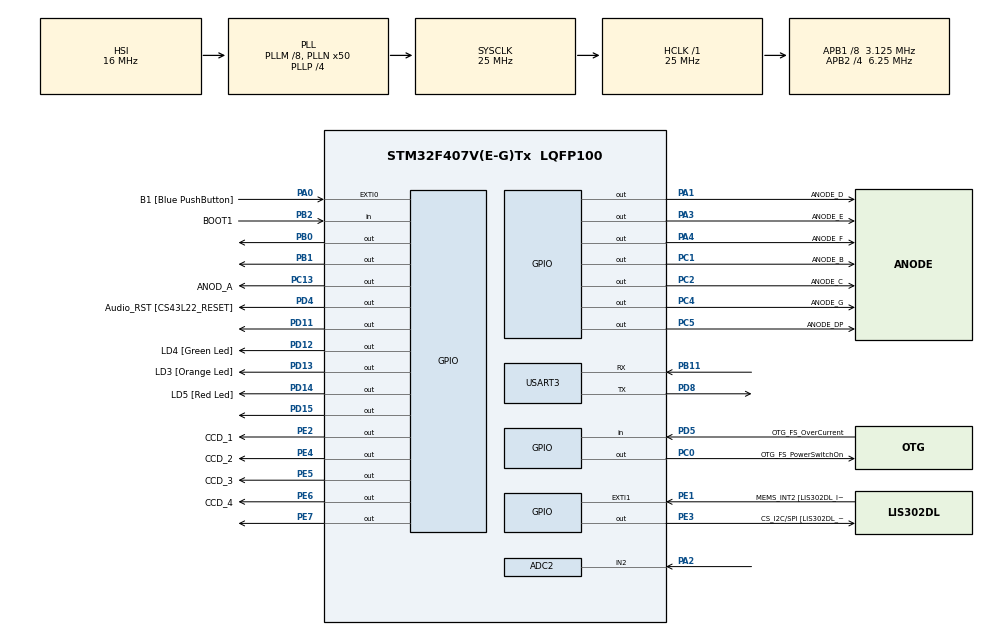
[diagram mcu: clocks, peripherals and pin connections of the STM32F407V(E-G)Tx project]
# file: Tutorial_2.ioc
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ADC2.Channel-0\#ChannelRegularConversion=ADC_CHANNEL_2
ADC2.ClockPrescaler=ADC_CLOCK_SYNC_PCLK_DIV2
ADC2.ContinuousConvMode=DISABLE
ADC2.DMAContinuousRequests=DISABLE
ADC2.DataAlign=ADC_DATAALIGN_RIGHT
ADC2.DiscontinuousConvMode=DISABLE
ADC2.EOCSelection=ADC_EOC_SINGLE_CONV
ADC2.EnableAnalogWatchDog=false
ADC2.ExternalTrigConv=ADC_EXTERNALTRIGCONV_T3_TRGO
ADC2.ExternalTrigConvEdge=ADC_EXTERNALTRIGCONVEDGE_RISING
ADC2.InjNumberOfConversion=0
ADC2.NbrOfConversion=1
ADC2.NbrOfConversionFlag=1
ADC2.Rank-0\#ChannelRegularConversion=1
ADC2.Resolution=ADC_RESOLUTION_8B
ADC2.SamplingTime-0\#ChannelRegularConversion=ADC_SAMPLETIME_3CYCLES
ADC2.ScanConvMode=DISABLE
Mcu.Family=STM32F4
Mcu.Name=STM32F407V(E-G)Tx
Mcu.Package=LQFP100
NVIC.PriorityGroup=NVIC_PRIORITYGROUP_0
NVIC.TIM2_IRQn=true\:0\:0\:false\:false\:true\:true
NVIC.USART3_IRQn=true\:0\:0\:false\:false\:true\:true
PA0-WKUP.GPIO_Label=B1 [Blue PushButton]
PA0-WKUP.GPIO_ModeDefaultEXTI=GPIO_MODE_EVT_RISING
PA0-WKUP.GPIO_PuPd=GPIO_NOPULL
PA0-WKUP.Signal=GPXTI0
PA1.GPIO_Label=ANODE_D
PA1.Signal=GPIO_Output
PA10.GPIO_Label=OTG_FS_ID
PA10.GPIO_Mode=GPIO_MODE_AF_PP
PA10.GPIO_PuPd=GPIO_NOPULL
PA10.GPIO_Speed=GPIO_SPEED_FREQ_LOW
PA10.Signal=USB_OTG_FS_ID
PA11.GPIO_Label=OTG_FS_DM
PA11.GPIO_Mode=GPIO_MODE_AF_PP
PA11.GPIO_PuPd=GPIO_NOPULL
PA11.GPIO_Speed=GPIO_SPEED_FREQ_LOW
PA11.Signal=USB_OTG_FS_DM
PA12.GPIO_Label=OTG_FS_DP
PA12.GPIO_Mode=GPIO_MODE_AF_PP
PA12.GPIO_PuPd=GPIO_NOPULL
PA12.GPIO_Speed=GPIO_SPEED_FREQ_LOW
PA12.Signal=USB_OTG_FS_DP
PA13.GPIO_Label=SWDIO
PA13.Signal=SYS_JTMS-SWDIO
PA14.GPIO_Label=SWCLK
PA14.Signal=SYS_JTCK-SWCLK
PA2.Signal=ADCx_IN2
PA3.GPIO_Label=ANODE_E
PA3.Signal=GPIO_Output
PA4.GPIO_Label=ANODE_F
PA4.Signal=GPIO_Output
PA5.GPIO_Label=SPI1_SCK [LIS302DL_SCL/SPC]
PA5.GPIO_Mode=GPIO_MODE_AF_PP
PA5.GPIO_PuPd=GPIO_NOPULL
PA5.GPIO_Speed=GPIO_SPEED_FREQ_LOW
PA5.Signal=SPI1_SCK
PA6.GPIO_Label=SPI1_MISO [LIS302DL_SDO]
PA6.GPIO_Mode=GPIO_MODE_AF_PP
PA6.GPIO_PuPd=GPIO_NOPULL
PA6.GPIO_Speed=GPIO_SPEED_FREQ_LOW
PA6.Signal=SPI1_MISO
PA7.GPIO_Label=SPI1_MOSI [LIS302DL_SDA/SDI/SDO]
PA7.GPIO_Mode=GPIO_MODE_AF_PP
PA7.GPIO_PuPd=GPIO_NOPULL
PA7.GPIO_Speed=GPIO_SPEED_FREQ_LOW
PA7.Signal=SPI1_MOSI
PA9.GPIO_Label=VBUS_FS
PA9.GPIO_Mode=GPIO_MODE_INPUT
PA9.GPIO_PuPd=GPIO_NOPULL
PA9.Signal=USB_OTG_FS_VBUS
PB0.Signal=GPIO_Output
PB1.Signal=GPIO_Output
PB10.GPIO_Label=CLK_IN [MP45DT02_CLK]
PB10.GPIO_Mode=GPIO_MODE_AF_PP
PB10.GPIO_PuPd=GPIO_NOPULL
PB10.GPIO_Speed=GPIO_SPEED_FREQ_LOW
PB10.Signal=I2S2_CK
PB11.Mode=Asynchronous
PB11.Signal=USART3_RX
PB2.GPIO_Label=BOOT1
PB2.GPIO_Mode=GPIO_MODE_INPUT
PB2.GPIO_PuPd=GPIO_NOPULL
PB2.Signal=GPIO_Input
PB3.GPIO_Label=SWO
PB3.Signal=SYS_JTDO-SWO
PB6.GPIO_Label=Audio_SCL [CS43L22_SCL]
PB6.GPIO_Mode=GPIO_MODE_AF_OD
PB6.GPIO_PuPd=GPIO_NOPULL
PB6.GPIO_Speed=GPIO_SPEED_FREQ_LOW
PB6.Signal=I2C1_SCL
PB9.GPIO_Label=Audio_SDA [CS43L22_SDA]
PB9.GPIO_Mode=GPIO_MODE_AF_OD
PB9.GPIO_PuPd=GPIO_NOPULL
PB9.GPIO_Speed=GPIO_SPEED_FREQ_LOW
PB9.Signal=I2C1_SDA
PC0.GPIO_Label=OTG_FS_PowerSwitchOn
PC0.GPIO_PuPd=GPIO_NOPULL
PC0.GPIO_Speed=GPIO_SPEED_FREQ_LOW
PC0.PinState=GPIO_PIN_SET
PC0.Signal=GPIO_Output
PC1.GPIO_Label=ANODE_B
PC1.Signal=GPIO_Output
PC10.GPIO_Label=I2S3_SCK [CS43L22_SCLK]
PC10.GPIO_Mode=GPIO_MODE_AF_PP
PC10.GPIO_PuPd=GPIO_NOPULL
PC10.GPIO_Speed=GPIO_SPEED_FREQ_LOW
PC10.Signal=I2S3_CK
PC12.GPIO_Label=I2S3_SD [CS43L22_SDIN]
PC12.GPIO_Mode=GPIO_MODE_AF_PP
PC12.GPIO_PuPd=GPIO_NOPULL
PC12.GPIO_Speed=GPIO_SPEED_FREQ_LOW
PC12.Signal=I2S3_SD
PC13-ANTI_TAMP.GPIO_Label=ANOD_A
PC13-ANTI_TAMP.Signal=GPIO_Output
PC14-OSC32_IN.GPIO_Label=PC14-OSC32_IN
PC14-OSC32_IN.Signal=RCC_OSC32_IN
PC15-OSC32_OUT.GPIO_Label=PC15-OSC32_OUT
PC15-OSC32_OUT.Signal=RCC_OSC32_OUT
PC2.GPIO_Label=ANODE_C
PC2.Signal=GPIO_Output
PC3.GPIO_Label=PDM_OUT [MP45DT02_DOUT]
PC3.GPIO_Mode=GPIO_MODE_AF_PP
PC3.GPIO_PuPd=GPIO_NOPULL
PC3.GPIO_Speed=GPIO_SPEED_FREQ_LOW
PC3.Signal=I2S2_SD
PC4.GPIO_Label=ANODE_G
PC4.Signal=GPIO_Output
PC5.GPIO_Label=ANODE_DP
PC5.Signal=GPIO_Output
PC7.GPIO_Label=I2S3_MCK [CS43L22_MCLK]
PC7.GPIO_Mode=GPIO_MODE_AF_PP
PC7.GPIO_PuPd=GPIO_NOPULL
PC7.GPIO_Speed=GPIO_SPEED_FREQ_LOW
PC7.Signal=I2S3_MCK
PD11.Signal=GPIO_Output
PD12.GPIO_Label=LD4 [Green Led]
PD12.GPIO_PuPd=GPIO_NOPULL
PD12.GPIO_Speed=GPIO_SPEED_FREQ_LOW
PD12.Signal=GPIO_Output
PD13.GPIO_Label=LD3 [Orange Led]
PD13.GPIO_PuPd=GPIO_NOPULL
PD13.GPIO_Speed=GPIO_SPEED_FREQ_LOW
PD13.Signal=GPIO_Output
PD14.GPIO_Label=LD5 [Red Led]
PD14.GPIO_PuPd=GPIO_NOPULL
PD14.GPIO_Speed=GPIO_SPEED_FREQ_LOW
PD14.Signal=GPIO_Output
PD15.GPIO_ModeDefaultOutputPP=GPIO_MODE_OUTPUT_PP
PD15.Signal=GPIO_Output
PD4.GPIO_Label=Audio_RST [CS43L22_RESET]
PD4.GPIO_PuPd=GPIO_NOPULL
PD4.GPIO_Speed=GPIO_SPEED_FREQ_LOW
PD4.Signal=GPIO_Output
PD5.GPIO_Label=OTG_FS_OverCurrent
PD5.GPIO_Mode=GPIO_MODE_INPUT
PD5.GPIO_PuPd=GPIO_NOPULL
PD5.Signal=GPIO_Input
PD8.Mode=Asynchronous
PD8.Signal=USART3_TX
PE1.GPIO_Label=MEMS_INT2 [LIS302DL_INT2]
PE1.GPIO_ModeDefaultEXTI=GPIO_MODE_EVT_RISING
PE1.GPIO_PuPd=GPIO_NOPULL
PE1.Signal=GPXTI1
PE2.GPIO_Label=CCD_1
PE2.Signal=GPIO_Output
PE3.GPIO_Label=CS_I2C/SPI [LIS302DL_CS_I2C/SPI]
PE3.GPIO_PuPd=GPIO_NOPULL
PE3.GPIO_Speed=GPIO_SPEED_FREQ_LOW
PE3.Signal=GPIO_Output
PE4.GPIO_Label=CCD_2
PE4.Signal=GPIO_Output
PE5.GPIO_Label=CCD_3
PE5.Signal=GPIO_Output
PE6.GPIO_Label=CCD_4
PE6.Signal=GPIO_Output
PE7.Signal=GPIO_Output
PH0-OSC_IN.GPIO_Label=PH0-OSC_IN
PH0-OSC_IN.Signal=RCC_OSC_IN
PH1-OSC_OUT.GPIO_Label=PH1-OSC_OUT
PH1-OSC_OUT.Signal=RCC_OSC_OUT
ProjectManager.HeapSize=0x200
ProjectManager.StackSize=0x400
ProjectManager.TargetToolchain=MDK-ARM V5
RCC.48MHZClocksFreq_Value=14285714.285714285
RCC.AHBFreq_Value=25000000
RCC.APB1CLKDivider=RCC_HCLK_DIV8
RCC.APB1Freq_Value=3125000
RCC.APB1TimFreq_Value=6250000
RCC.APB2CLKDivider=RCC_HCLK_DIV4
RCC.APB2Freq_Value=6250000
RCC.APB2TimFreq_Value=12500000
RCC.CortexFreq_Value=25000000
RCC.HCLKFreq_Value=25000000
RCC.HSE_VALUE=8000000
RCC.HSI_VALUE=16000000
RCC.LSE_VALUE=32768
RCC.PLLM=8
RCC.PLLN=50
RCC.PLLP=RCC_PLLP_DIV4
RCC.PLLQ=7
RCC.SYSCLKFreq_VALUE=25000000
RCC.SYSCLKSource=RCC_SYSCLKSOURCE_PLLCLK
RCC.VCOOutputFreq_Value=100000000
SH.ADCx_IN2.0=ADC2_IN2,IN2
TIM2.Period=15
TIM2.Prescaler=6250
TIM2.TIM_MasterOutputTrigger=TIM_TRGO_UPDATE
USART3.VirtualMode=VM_ASYNC
VP_TIM2_VS_ClockSourceINT.Mode=Internal
board=STM32F4DISCOVERY

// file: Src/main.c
/**
  ******************************************************************************
  * File Name          : main.c
  * Description        : Main program body
  ******************************************************************************
  ** This notice applies to any and all portions of this file
  * that are not between comment pairs USER CODE BEGIN and
  * USER CODE END. Other portions of this file, whether
  * inserted by the user or by software development tools
  * are owned by their respective copyright owners.
  *
  * COPYRIGHT(c) 2017 STMicroelectronics
  *
  * Redistribution and use in source and binary forms, with or without modification,
  * are permitted provided that the following conditions are met:
  *   1. Redistributions of source code must retain the above copyright notice,
  *      this list of conditions and the following disclaimer.
  *   2. Redistributions in binary form must reproduce the above copyright notice,
  *      this list of conditions and the following disclaimer in the documentation
  *      and/or other materials provided with the distribution.
  *   3. Neither the name of STMicroelectronics nor the names of its contributors
  *      may be used to endorse or promote products derived from this software
  *      without specific prior written permission.
  *
  * THIS SOFTWARE IS PROVIDED BY THE COPYRIGHT HOLDERS AND CONTRIBUTORS "AS IS"
  * AND ANY EXPRESS OR IMPLIED WARRANTIES, INCLUDING, BUT NOT LIMITED TO, THE
  * IMPLIED WARRANTIES OF MERCHANTABILITY AND FITNESS FOR A PARTICULAR PURPOSE ARE
  * DISCLAIMED. IN NO EVENT SHALL THE COPYRIGHT HOLDER OR CONTRIBUTORS BE LIABLE
  * FOR ANY DIRECT, INDIRECT, INCIDENTAL, SPECIAL, EXEMPLARY, OR CONSEQUENTIAL
  * DAMAGES (INCLUDING, BUT NOT LIMITED TO, PROCUREMENT OF SUBSTITUTE GOODS OR
  * SERVICES; LOSS OF USE, DATA, OR PROFITS; OR BUSINESS INTERRUPTION) HOWEVER
  * CAUSED AND ON ANY THEORY OF LIABILITY, WHETHER IN CONTRACT, STRICT LIABILITY,
  * OR TORT (INCLUDING NEGLIGENCE OR OTHERWISE) ARISING IN ANY WAY OUT OF THE USE
  * OF THIS SOFTWARE, EVEN IF ADVISED OF THE POSSIBILITY OF SUCH DAMAGE.
  *
  ******************************************************************************
  */
#include "main.h"
#include "stm32f4xx_hal.h"
#include "adc.h"
#include "tim.h"
#include "usart.h"
#include "gpio.h"

const int BUFFER_SIZE = 32000;
const int SEND_BUF_SIZE = 40;
const int REC_TIME = 3; //s
uint8_t sendBuffer[SEND_BUF_SIZE];
uint8_t bufferA[BUFFER_SIZE];
uint8_t adcInterruptFlag;

void SystemClock_Config(void);
void PWR_StandbyMode(void);

int main(void)
{
  HAL_Init();
  /* Configure the system clock */
  SystemClock_Config();

  /* Initialize all configured peripherals */
  MX_GPIO_Init();
  MX_ADC2_Init();
  MX_TIM2_Init();
  MX_USART3_UART_Init();

	//Start the Timer as interrupt
	HAL_TIM_Base_Start_IT(&htim2);

	uint8_t adcVal;
	int ind;

	//Initialize the buffer size
	for(int i = 0; i < BUFFER_SIZE; i++)
	{
		bufferA[i] = 0;
	}
	for(int i = 0; i < SEND_BUF_SIZE; i++)
	{
		sendBuffer[i] = 0;
	}

	// Turn blue led on to check system started working
	HAL_GPIO_WritePin(GPIOD, GPIO_PIN_15, GPIO_PIN_SET); //Blue LED

  while (1)
  {
		// start the program if the blue button is pressed
		if (HAL_GPIO_ReadPin(GPIOA, GPIO_PIN_0))
		{
			// send Start signal to nucleo board
			uint8_t start[5] = {0x73,0x74,0x61,0x72,0x74};
			HAL_UART_Transmit(&huart3, &start[0], 5, 2000);
			HAL_StatusTypeDef status = HAL_TIMEOUT;

			HAL_GPIO_WritePin(GPIOD, GPIO_PIN_14, GPIO_PIN_SET); //Red LED
			HAL_Delay(1000);
			HAL_GPIO_WritePin(GPIOD, GPIO_PIN_14, GPIO_PIN_RESET);	//Red LED
			HAL_GPIO_WritePin(GPIOD, GPIO_PIN_13, GPIO_PIN_SET); 		//Orange LED
			HAL_Delay(1000);
			HAL_GPIO_WritePin(GPIOD, GPIO_PIN_13, GPIO_PIN_RESET);	//Orange LED
			HAL_GPIO_WritePin(GPIOD, GPIO_PIN_12, GPIO_PIN_SET); 		//Green LED

			// start adc
			HAL_ADC_Start(&hadc2);

			ind = 0;
			// fill the buffer until it's full
			while(ind < BUFFER_SIZE)
			{
				// store the adc value when interrupt happens
				while(adcInterruptFlag)
				{
					adcInterruptFlag = 0;
					adcVal = HAL_ADC_GetValue(&hadc2);
					bufferA[ind] = adcVal;
					ind++;
				}
			}
			// indicate the transmission has started
			HAL_GPIO_WritePin(GPIOD, GPIO_PIN_12, GPIO_PIN_RESET); 	//Green LED
			HAL_GPIO_WritePin(GPIOD, GPIO_PIN_14, GPIO_PIN_SET);	//Red LED

			// partition the buffer by SEND_BUF_SIZE
			for(int k=0; k<BUFFER_SIZE; k+=SEND_BUF_SIZE)
			{
				for(int j=0; j<SEND_BUF_SIZE; j++)
				{
					sendBuffer[j] = bufferA[k+j];
				}
				// While the transmit is not complete
				while(status != HAL_OK)
				{
					status = HAL_UART_Transmit(&huart3, &sendBuffer[0], SEND_BUF_SIZE, 2000);
				}
				HAL_Delay(8);
				status = HAL_TIMEOUT;
			}
			// indicate the transmission is done
			HAL_GPIO_WritePin(GPIOD, GPIO_PIN_14, GPIO_PIN_RESET); 		//Red LED

			HAL_ADC_Stop(&hadc2);
			// Task is done, go to power saving mode
			PWR_StandbyMode();
		}
	}
}

/** System Clock Configuration
*/
void SystemClock_Config(void)
{

  RCC_OscInitTypeDef RCC_OscInitStruct;
  RCC_ClkInitTypeDef RCC_ClkInitStruct;

    /**Configure the main internal regulator output voltage
    */
  __HAL_RCC_PWR_CLK_ENABLE();

  __HAL_PWR_VOLTAGESCALING_CONFIG(PWR_REGULATOR_VOLTAGE_SCALE1);

    /**Initializes the CPU, AHB and APB busses clocks
    */
  RCC_OscInitStruct.OscillatorType = RCC_OSCILLATORTYPE_HSI;
  RCC_OscInitStruct.HSIState = RCC_HSI_ON;
  RCC_OscInitStruct.HSICalibrationValue = 16;
  RCC_OscInitStruct.PLL.PLLState = RCC_PLL_ON;
  RCC_OscInitStruct.PLL.PLLSource = RCC_PLLSOURCE_HSI;
  RCC_OscInitStruct.PLL.PLLM = 8;
  RCC_OscInitStruct.PLL.PLLN = 50;
  RCC_OscInitStruct.PLL.PLLP = RCC_PLLP_DIV4;
  RCC_OscInitStruct.PLL.PLLQ = 7;
  if (HAL_RCC_OscConfig(&RCC_OscInitStruct) != HAL_OK)
  {
    _Error_Handler(__FILE__, __LINE__);
  }

    /**Initializes the CPU, AHB and APB busses clocks
    */
  RCC_ClkInitStruct.ClockType = RCC_CLOCKTYPE_HCLK|RCC_CLOCKTYPE_SYSCLK
                              |RCC_CLOCKTYPE_PCLK1|RCC_CLOCKTYPE_PCLK2;
  RCC_ClkInitStruct.SYSCLKSource = RCC_SYSCLKSOURCE_PLLCLK;
  RCC_ClkInitStruct.AHBCLKDivider = RCC_SYSCLK_DIV1;
  RCC_ClkInitStruct.APB1CLKDivider = RCC_HCLK_DIV8;
  RCC_ClkInitStruct.APB2CLKDivider = RCC_HCLK_DIV4;

  if (HAL_RCC_ClockConfig(&RCC_ClkInitStruct, FLASH_LATENCY_0) != HAL_OK)
  {
    _Error_Handler(__FILE__, __LINE__);
  }

    /**Configure the Systick interrupt time
    */
  HAL_SYSTICK_Config(HAL_RCC_GetHCLKFreq()/1000);

    /**Configure the Systick
    */
  HAL_SYSTICK_CLKSourceConfig(SYSTICK_CLKSOURCE_HCLK);

  /* SysTick_IRQn interrupt configuration */
  HAL_NVIC_SetPriority(SysTick_IRQn, 0, 0);
}

/* USER CODE BEGIN 4 */
/**
  * @brief  When the function is called, the board goes to standby mode to
						save power consumption. Blue button is used to wake up.
  * @param  None
  * @retval None
  */
void PWR_StandbyMode(void)
{
  __HAL_RCC_PWR_CLK_ENABLE();

  if(__HAL_PWR_GET_FLAG(PWR_FLAG_SB) != RESET)
    __HAL_PWR_CLEAR_FLAG(PWR_FLAG_SB);

  HAL_Delay(500);
	//PWR_WAKEUP_PIN1
  HAL_PWR_DisableWakeUpPin(PWR_WAKEUP_PIN1);
  __HAL_PWR_CLEAR_FLAG(PWR_FLAG_WU);
  HAL_PWR_EnableWakeUpPin(PWR_WAKEUP_PIN1);
  HAL_PWR_EnterSTANDBYMode();
}

/* USER CODE END 4 */

void _Error_Handler(char * file, int line)
{
  while(1)
  {
  }
}

/************************ (C) COPYRIGHT STMicroelectronics *****END OF FILE****/
